# MCXC444 register map
Vendor: NXP Semiconductors; Series: MCX; File version: 1.6
CPU: CM0PLUS r0p0, little endian, no MPU, no FPU, VTOR, 2 interrupt priority bits
Registers are 32-bit, read-write, reset 0x0 unless marked. A register's access mark holds for its fields unless they carry their own. Offsets are from the block's base; [hi:lo] are bit positions; {n}, {i} and the like mark numbered series.

## DMAMUX0 — DMA channel multiplexor
Base 0x40021000; register names take the prefix DMAMUX0_
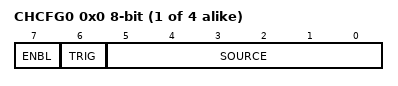
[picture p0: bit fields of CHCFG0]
{0x0+i} CHCFG{i} (i=0..3) 8-bit — Channel Configuration register
  [7] ENBL — DMA Channel Enable
    0=b0 (DMA channel is disabled. This mode is primarily used during configuration of the DMAMux. The DMA has separate channel enables/disables, which should be used to disable or reconfigure a DMA channel.); 1=b1 (DMA channel is enabled)
  [6] TRIG — DMA Channel Trigger Enable
    0=b0 (Triggering is disabled. If triggering is disabled and ENBL is set, the DMA Channel will simply route the specified source to the DMA channel. (Normal mode)); 1=b1 (Triggering is enabled. If triggering is enabled and ENBL is set, the DMAMUX is in Periodic Trigger mode.)
  [5:0] SOURCE — DMA Channel Source (Slot)
    0=b000000 (Disable_Signal); 2=b000010 (LPUART0_Rx_Signal); 3=b000011 (LPUART0_Tx_Signal); 4=b000100 (LPUART1_Rx_Signal); 5=b000101 (LPUART1_Tx_Signal); 6=b000110 (UART2_Rx_Signal); 7=b000111 (UART2_Tx_Signal); 10=b001010 (FlexIO_Channel0_Signal); 11=b001011 (FlexIO_Channel1_Signal); 12=b001100 (FlexIO_Channel2_Signal); 13=b001101 (FlexIO_Channel3_Signal); 14=b001110 (I2S0_Rx_Signal); 15=b001111 (I2S0_Tx_Signal); 16=b010000 (SPI0_Rx_Signal); 17=b010001 (SPI0_Tx_Signal); 18=b010010 (SPI1_Rx_Signal); 19=b010011 (SPI1_Tx_Signal); 22=b010110 (I2C0_Signal); 23=b010111 (I2C1_Signal); 24=b011000 (TPM0_Channel0_Signal); 25=b011001 (TPM0_Channel1_Signal); 26=b011010 (TPM0_Channel2_Signal); 27=b011011 (TPM0_Channel3_Signal); 28=b011100 (TPM0_Channel4_Signal); 29=b011101 (TPM0_Channel5_Signal); 32=b100000 (TPM1_Channel0_Signal); 33=b100001 (TPM1_Channel1_Signal); 34=b100010 (TPM2_Channel0_Signal); 35=b100011 (TPM2_Channel1_Signal); 40=b101000 (ADC0_Signal); 42=b101010 (CMP0_Signal); 45=b101101 (DAC0_Signal); 49=b110001 (Port_A_Signal); 51=b110011 (Port_C_Signal); 52=b110100 (Port_D_Signal); 54=b110110 (TPM0_Overflow_Signal); 55=b110111 (TPM1_Overflow_Signal); 56=b111000 (TPM2_Overflow_Signal); 60=b111100 (AlwaysOn60_Signal); 61=b111101 (AlwaysOn61_Signal); 62=b111110 (AlwaysOn62_Signal); 63=b111111 (AlwaysOn63_Signal)

## PIT — Periodic Interrupt Timer
Base 0x40037000; register names take the prefix PIT_
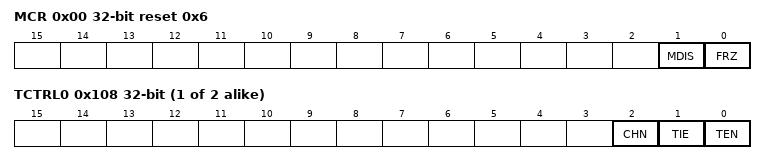
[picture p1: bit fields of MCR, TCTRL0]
0x00 MCR reset 0x6 — PIT Module Control Register
  [1] MDIS — Module Disable - (PIT section)
    0=b0 (Clock for standard PIT timers is enabled.); 1=b1 (Clock for standard PIT timers is disabled.)
  [0] FRZ — Freeze
    0=b0 (Timers continue to run in Debug mode.); 1=b1 (Timers are stopped in Debug mode.)
0xE0 LTMR64H ro — PIT Upper Lifetime Timer Register
  [31:0] LTH — Life Timer value
0xE4 LTMR64L ro — PIT Lower Lifetime Timer Register
  [31:0] LTL — Life Timer value
{0x100+0x10*i} LDVAL{i} (i=0..1) — Timer Load Value Register
  [31:0] TSV — Timer Start Value
{0x104+0x10*i} CVAL{i} (i=0..1) ro — Current Timer Value Register
  [31:0] TVL — Current Timer Value
{0x108+0x10*i} TCTRL{i} (i=0..1) — Timer Control Register
  [2] CHN — Chain Mode
    0=b0 (Timer is not chained.); 1=b1 (Timer is chained to previous timer. For example, for Channel 2, if this field is set, Timer 2 is chained to Timer 1.)
  [1] TIE — Timer Interrupt Enable
    0=b0 (Interrupt requests from Timer n are disabled.); 1=b1 (Interrupt will be requested whenever TIF is set.)
  [0] TEN — Timer Enable
    0=b0 (Timer n is disabled.); 1=b1 (Timer n is enabled.)
{0x10C+0x10*i} TFLG{i} (i=0..1) — Timer Flag Register
  [0] TIF — Timer Interrupt Flag
    0=b0 (Timeout has not yet occurred.); 1=b1 (Timeout has occurred.)

## DAC0 — 12-Bit Digital-to-Analog Converter
Base 0x4003F000; register names take the prefix DAC0_
{0x0+2i} DAT{i}L (i=0..1) 8-bit — DAC Data Low Register
  [7:0] DATA0
{0x1+2i} DAT{i}H (i=0..1) 8-bit — DAC Data High Register
  [3:0] DATA1
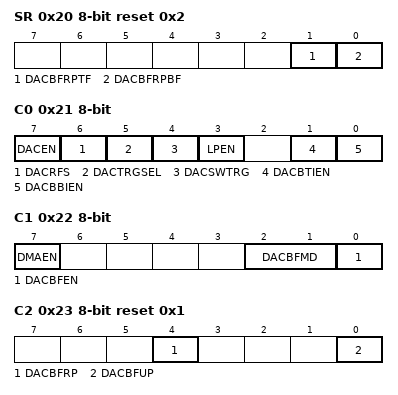
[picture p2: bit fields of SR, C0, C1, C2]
0x20 SR 8-bit reset 0x2 — DAC Status Register
  [1] DACBFRPTF — DAC Buffer Read Pointer Top Position Flag
    0=b0 (The DAC buffer read pointer is not zero.); 1=b1 (The DAC buffer read pointer is zero.)
  [0] DACBFRPBF — DAC Buffer Read Pointer Bottom Position Flag
    0=b0 (The DAC buffer read pointer is not equal to C2[DACBFUP].); 1=b1 (The DAC buffer read pointer is equal to C2[DACBFUP].)
0x21 C0 8-bit — DAC Control Register
  [7] DACEN — DAC Enable
    0=b0 (The DAC system is disabled.); 1=b1 (The DAC system is enabled.)
  [6] DACRFS — DAC Reference Select
    0=b0 (The DAC selects DACREF_1 as the reference voltage.); 1=b1 (The DAC selects DACREF_2 as the reference voltage.)
  [5] DACTRGSEL — DAC Trigger Select
    0=b0 (The DAC hardware trigger is selected.); 1=b1 (The DAC software trigger is selected.)
  [4] DACSWTRG — DAC Software Trigger
    0=b0 (The DAC soft trigger is not valid.); 1=b1 (The DAC soft trigger is valid.)
  [3] LPEN — DAC Low Power Control
    0=b0 (High-Power mode); 1=b1 (Low-Power mode)
  [1] DACBTIEN — DAC Buffer Read Pointer Top Flag Interrupt Enable
    0=b0 (The DAC buffer read pointer top flag interrupt is disabled.); 1=b1 (The DAC buffer read pointer top flag interrupt is enabled.)
  [0] DACBBIEN — DAC Buffer Read Pointer Bottom Flag Interrupt Enable
    0=b0 (The DAC buffer read pointer bottom flag interrupt is disabled.); 1=b1 (The DAC buffer read pointer bottom flag interrupt is enabled.)
0x22 C1 8-bit — DAC Control Register 1
  [7] DMAEN — DMA Enable Select
    0=b0 (DMA is disabled.); 1=b1 (DMA is enabled. When DMA is enabled, the DMA request will be generated by original interrupts. The interrupts will not be presented on this module at the same time.)
  [2:1] DACBFMD — DAC Buffer Work Mode Select
    0=b00 (Normal mode); 2=b10 (One-Time Scan mode); 3=b11 (FIFO mode)
  [0] DACBFEN — DAC Buffer Enable
    0=b0 (Buffer read pointer is disabled. The converted data is always the first word of the buffer.); 1=b1 (Buffer read pointer is enabled. The converted data is the word that the read pointer points to. It means converted data can be from any word of the buffer.)
0x23 C2 8-bit reset 0x1 — DAC Control Register 2
  [4] DACBFRP — DAC Buffer Read Pointer
  [0] DACBFUP — DAC Buffer Upper Limit
